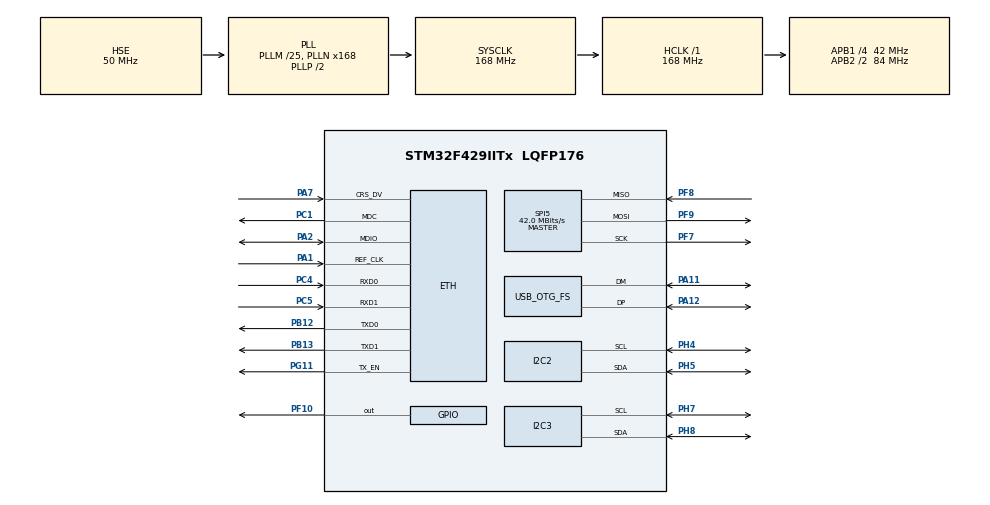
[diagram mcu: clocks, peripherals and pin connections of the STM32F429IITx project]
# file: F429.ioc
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ETH.MediaInterface=HAL_ETH_RMII_MODE
FREERTOS.HEAP_NUMBER=5
FREERTOS.Tasks01=DataRCCTask,33,256,StartDataRCCTask,Default,NULL,Static,DataRCCTaskBuffer,DataRCCTaskControlBlock
FREERTOS.configMAX_TASK_NAME_LEN=32
FREERTOS.configUSE_NEWLIB_REENTRANT=1
LWIP.BSP.number=1
LWIP.GATEWAY_ADDRESS=192.168.000.100
LWIP.IP_ADDRESS=192.168.000.001
LWIP.LWIP_DHCP=0
LWIP.NETMASK_ADDRESS=255.255.255.000
LWIP.Version=v2.1.2_Cube
LWIP0.BSP.STBoard=false
LWIP0.BSP.api=BSP_COMPONENT_DRIVER
LWIP0.BSP.component=LAN8742
LWIP0.BSP.instance=LAN8742
LWIP0.BSP.name=Driver_PHY
LWIP0.BSP.semaphore=S_LAN8742
LWIP0.BSP.solution=LAN8742
Mcu.Family=STM32F4
Mcu.Name=STM32F429IITx
Mcu.Package=LQFP176
NVIC.ETH_IRQn=true\:5\:0\:false\:false\:true\:true\:false\:true\:true
NVIC.OTG_FS_IRQn=true\:5\:0\:false\:false\:true\:true\:false\:true\:true
NVIC.PriorityGroup=NVIC_PRIORITYGROUP_4
NVIC.TIM7_IRQn=true\:15\:0\:false\:false\:true\:false\:false\:true\:true
NVIC.TimeBase=TIM7_IRQn
NVIC.TimeBaseIP=TIM7
PA1.Mode=RMII
PA1.Signal=ETH_REF_CLK
PA11.Mode=Device_Only
PA11.Signal=USB_OTG_FS_DM
PA12.Mode=Device_Only
PA12.Signal=USB_OTG_FS_DP
PA13.Mode=Serial_Wire
PA13.Signal=SYS_JTMS-SWDIO
PA14.Mode=Serial_Wire
PA14.Signal=SYS_JTCK-SWCLK
PA2.Mode=RMII
PA2.Signal=ETH_MDIO
PA7.Mode=RMII
PA7.Signal=ETH_CRS_DV
PB12.Mode=RMII
PB12.Signal=ETH_TXD0
PB13.Mode=RMII
PB13.Signal=ETH_TXD1
PC1.Mode=RMII
PC1.Signal=ETH_MDC
PC4.Mode=RMII
PC4.Signal=ETH_RXD0
PC5.Mode=RMII
PC5.Signal=ETH_RXD1
PF10.Signal=GPIO_Output
PF7.Mode=Full_Duplex_Master
PF7.Signal=SPI5_SCK
PF8.Mode=Full_Duplex_Master
PF8.Signal=SPI5_MISO
PF9.Mode=Full_Duplex_Master
PF9.Signal=SPI5_MOSI
PG11.Mode=RMII
PG11.Signal=ETH_TX_EN
PH0/OSC_IN.Mode=HSE-External-Clock-Source
PH0/OSC_IN.Signal=RCC_OSC_IN
PH1/OSC_OUT.Mode=HSE-External-Clock-Source
PH1/OSC_OUT.Signal=RCC_OSC_OUT
PH4.Mode=I2C
PH4.Signal=I2C2_SCL
PH5.Mode=I2C
PH5.Signal=I2C2_SDA
PH7.Mode=I2C
PH7.Signal=I2C3_SCL
PH8.Mode=I2C
PH8.Signal=I2C3_SDA
ProjectManager.HeapSize=0x200
ProjectManager.StackSize=0x400
ProjectManager.TargetToolchain=STM32CubeIDE
RCC.48MHZClocksFreq_Value=48000000
RCC.AHBFreq_Value=168000000
RCC.APB1CLKDivider=RCC_HCLK_DIV4
RCC.APB1Freq_Value=42000000
RCC.APB1TimFreq_Value=84000000
RCC.APB2CLKDivider=RCC_HCLK_DIV2
RCC.APB2Freq_Value=84000000
RCC.APB2TimFreq_Value=168000000
RCC.CortexFreq_Value=168000000
RCC.HCLKFreq_Value=168000000
RCC.HSE_VALUE=50000000
RCC.HSI_VALUE=16000000
RCC.LSE_VALUE=32768
RCC.PLLM=25
RCC.PLLN=168
RCC.PLLQ=7
RCC.SYSCLKFreq_VALUE=168000000
RCC.SYSCLKSource=RCC_SYSCLKSOURCE_PLLCLK
RCC.VCOOutputFreq_Value=336000000
SPI5.CalculateBaudRate=42.0 MBits/s
SPI5.Direction=SPI_DIRECTION_2LINES
SPI5.Mode=SPI_MODE_MASTER
SPI5.VirtualType=VM_MASTER
USB_DEVICE.CLASS_NAME_FS=CDC
USB_DEVICE.VirtualMode-CDC_FS=Cdc
USB_DEVICE.VirtualModeFS=Cdc_FS
USB_OTG_FS.VirtualMode=Device_Only
VP_FREERTOS_VS_CMSIS_V2.Mode=CMSIS_V2
VP_LWIP_VS_Enabled.Mode=Enabled
VP_SYS_VS_tim7.Mode=TIM7
VP_USB_DEVICE_VS_USB_DEVICE_CDC_FS.Mode=CDC_FS
board=custom

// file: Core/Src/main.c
/* USER CODE BEGIN Header */
/**
  ******************************************************************************
  * @file           : main.c
  * @brief          : Main program body
  ******************************************************************************
  * @attention
  *
  * Copyright (c) 2024 STMicroelectronics.
  * All rights reserved.
  *
  * This software is licensed under terms that can be found in the LICENSE file
  * in the root directory of this software component.
  * If no LICENSE file comes with this software, it is provided AS-IS.
  *
  ******************************************************************************
  */
/* USER CODE END Header */
#include "main.h"
#include "cmsis_os.h"
#include "lwip.h"
#include "usb_device.h"

typedef StaticTask_t osStaticThreadDef_t;

I2C_HandleTypeDef hi2c2;
I2C_HandleTypeDef hi2c3;

SPI_HandleTypeDef hspi5;

/* Definitions for DataRCCTask */
osThreadId_t DataRCCTaskHandle;
uint32_t DataRCCTaskBuffer[ 256 ];
osStaticThreadDef_t DataRCCTaskControlBlock;
const osThreadAttr_t DataRCCTask_attributes = {
  .name = "DataRCCTask",
  .cb_mem = &DataRCCTaskControlBlock,
  .cb_size = sizeof(DataRCCTaskControlBlock),
  .stack_mem = &DataRCCTaskBuffer[0],
  .stack_size = sizeof(DataRCCTaskBuffer),
  .priority = (osPriority_t) osPriorityAboveNormal1,
};

void SystemClock_Config(void);
static void MX_GPIO_Init(void);
static void MX_I2C3_Init(void);
static void MX_I2C2_Init(void);
static void MX_SPI5_Init(void);
void StartDataRCCTask(void *argument);

int main(void)
{

  /* MCU Configuration--------------------------------------------------------*/

  /* Reset of all peripherals, Initializes the Flash interface and the Systick. */
  HAL_Init();

  /* Configure the system clock */
  SystemClock_Config();

  /* Initialize all configured peripherals */
  MX_GPIO_Init();
  MX_I2C3_Init();
  MX_I2C2_Init();
  MX_SPI5_Init();

  /* Init scheduler */
  osKernelInitialize();

  /* Create the thread(s) */
  /* creation of DataRCCTask */
  DataRCCTaskHandle = osThreadNew(StartDataRCCTask, NULL, &DataRCCTask_attributes);

  /* Start scheduler */
  osKernelStart();

  /* We should never get here as control is now taken by the scheduler */

  /* Infinite loop */
  while (1)
  {

  }
}

void SystemClock_Config(void)
{
  RCC_OscInitTypeDef RCC_OscInitStruct = {0};
  RCC_ClkInitTypeDef RCC_ClkInitStruct = {0};

  /** Configure the main internal regulator output voltage
  */
  __HAL_RCC_PWR_CLK_ENABLE();
  __HAL_PWR_VOLTAGESCALING_CONFIG(PWR_REGULATOR_VOLTAGE_SCALE1);

  /** Initializes the RCC Oscillators according to the specified parameters
  * in the RCC_OscInitTypeDef structure.
  */
  RCC_OscInitStruct.OscillatorType = RCC_OSCILLATORTYPE_HSE;
  RCC_OscInitStruct.HSEState = RCC_HSE_BYPASS;
  RCC_OscInitStruct.PLL.PLLState = RCC_PLL_ON;
  RCC_OscInitStruct.PLL.PLLSource = RCC_PLLSOURCE_HSE;
  RCC_OscInitStruct.PLL.PLLM = 25;
  RCC_OscInitStruct.PLL.PLLN = 168;
  RCC_OscInitStruct.PLL.PLLP = RCC_PLLP_DIV2;
  RCC_OscInitStruct.PLL.PLLQ = 7;
  if (HAL_RCC_OscConfig(&RCC_OscInitStruct) != HAL_OK)
  {
    Error_Handler();
  }

  /** Initializes the CPU, AHB and APB buses clocks
  */
  RCC_ClkInitStruct.ClockType = RCC_CLOCKTYPE_HCLK|RCC_CLOCKTYPE_SYSCLK
                              |RCC_CLOCKTYPE_PCLK1|RCC_CLOCKTYPE_PCLK2;
  RCC_ClkInitStruct.SYSCLKSource = RCC_SYSCLKSOURCE_PLLCLK;
  RCC_ClkInitStruct.AHBCLKDivider = RCC_SYSCLK_DIV1;
  RCC_ClkInitStruct.APB1CLKDivider = RCC_HCLK_DIV4;
  RCC_ClkInitStruct.APB2CLKDivider = RCC_HCLK_DIV2;

  if (HAL_RCC_ClockConfig(&RCC_ClkInitStruct, FLASH_LATENCY_5) != HAL_OK)
  {
    Error_Handler();
  }
}

static void MX_I2C2_Init(void)
{

  hi2c2.Instance = I2C2;
  hi2c2.Init.ClockSpeed = 100000;
  hi2c2.Init.DutyCycle = I2C_DUTYCYCLE_2;
  hi2c2.Init.OwnAddress1 = 0;
  hi2c2.Init.AddressingMode = I2C_ADDRESSINGMODE_7BIT;
  hi2c2.Init.DualAddressMode = I2C_DUALADDRESS_DISABLE;
  hi2c2.Init.OwnAddress2 = 0;
  hi2c2.Init.GeneralCallMode = I2C_GENERALCALL_DISABLE;
  hi2c2.Init.NoStretchMode = I2C_NOSTRETCH_DISABLE;
  if (HAL_I2C_Init(&hi2c2) != HAL_OK)
  {
    Error_Handler();
  }

  /** Configure Analogue filter
  */
  if (HAL_I2CEx_ConfigAnalogFilter(&hi2c2, I2C_ANALOGFILTER_ENABLE) != HAL_OK)
  {
    Error_Handler();
  }

  /** Configure Digital filter
  */
  if (HAL_I2CEx_ConfigDigitalFilter(&hi2c2, 0) != HAL_OK)
  {
    Error_Handler();
  }

}

static void MX_I2C3_Init(void)
{

  hi2c3.Instance = I2C3;
  hi2c3.Init.ClockSpeed = 100000;
  hi2c3.Init.DutyCycle = I2C_DUTYCYCLE_2;
  hi2c3.Init.OwnAddress1 = 0;
  hi2c3.Init.AddressingMode = I2C_ADDRESSINGMODE_7BIT;
  hi2c3.Init.DualAddressMode = I2C_DUALADDRESS_DISABLE;
  hi2c3.Init.OwnAddress2 = 0;
  hi2c3.Init.GeneralCallMode = I2C_GENERALCALL_DISABLE;
  hi2c3.Init.NoStretchMode = I2C_NOSTRETCH_DISABLE;
  if (HAL_I2C_Init(&hi2c3) != HAL_OK)
  {
    Error_Handler();
  }

  /** Configure Analogue filter
  */
  if (HAL_I2CEx_ConfigAnalogFilter(&hi2c3, I2C_ANALOGFILTER_ENABLE) != HAL_OK)
  {
    Error_Handler();
  }

  /** Configure Digital filter
  */
  if (HAL_I2CEx_ConfigDigitalFilter(&hi2c3, 0) != HAL_OK)
  {
    Error_Handler();
  }

}

static void MX_SPI5_Init(void)
{

  /* SPI5 parameter configuration*/
  hspi5.Instance = SPI5;
  hspi5.Init.Mode = SPI_MODE_MASTER;
  hspi5.Init.Direction = SPI_DIRECTION_2LINES;
  hspi5.Init.DataSize = SPI_DATASIZE_8BIT;
  hspi5.Init.CLKPolarity = SPI_POLARITY_LOW;
  hspi5.Init.CLKPhase = SPI_PHASE_1EDGE;
  hspi5.Init.NSS = SPI_NSS_SOFT;
  hspi5.Init.BaudRatePrescaler = SPI_BAUDRATEPRESCALER_2;
  hspi5.Init.FirstBit = SPI_FIRSTBIT_MSB;
  hspi5.Init.TIMode = SPI_TIMODE_DISABLE;
  hspi5.Init.CRCCalculation = SPI_CRCCALCULATION_DISABLE;
  hspi5.Init.CRCPolynomial = 10;
  if (HAL_SPI_Init(&hspi5) != HAL_OK)
  {
    Error_Handler();
  }

}

static void MX_GPIO_Init(void)
{
  GPIO_InitTypeDef GPIO_InitStruct = {0};

  /* GPIO Ports Clock Enable */
  __HAL_RCC_GPIOF_CLK_ENABLE();
  __HAL_RCC_GPIOH_CLK_ENABLE();
  __HAL_RCC_GPIOC_CLK_ENABLE();
  __HAL_RCC_GPIOA_CLK_ENABLE();
  __HAL_RCC_GPIOB_CLK_ENABLE();
  __HAL_RCC_GPIOG_CLK_ENABLE();

  /*Configure GPIO pin Output Level */
  HAL_GPIO_WritePin(GPIOF, GPIO_PIN_10, GPIO_PIN_RESET);

  /*Configure GPIO pin : PF10 */
  GPIO_InitStruct.Pin = GPIO_PIN_10;
  GPIO_InitStruct.Mode = GPIO_MODE_OUTPUT_PP;
  GPIO_InitStruct.Pull = GPIO_NOPULL;
  GPIO_InitStruct.Speed = GPIO_SPEED_FREQ_LOW;
  HAL_GPIO_Init(GPIOF, &GPIO_InitStruct);

}

void StartDataRCCTask(void *argument)
{
  /* init code for USB_DEVICE */
  MX_USB_DEVICE_Init();

  /* init code for LWIP */
  MX_LWIP_Init();
  /* USER CODE BEGIN 5 */
  /* Infinite loop */
  for(;;)
  {
    osDelay(10);
  }
  /* USER CODE END 5 */
}

void HAL_TIM_PeriodElapsedCallback(TIM_HandleTypeDef *htim)
{
  if (htim->Instance == TIM7) {
    HAL_IncTick();
  }
}

void Error_Handler(void)
{
  __disable_irq();
  while (1)
  {
  }
}
